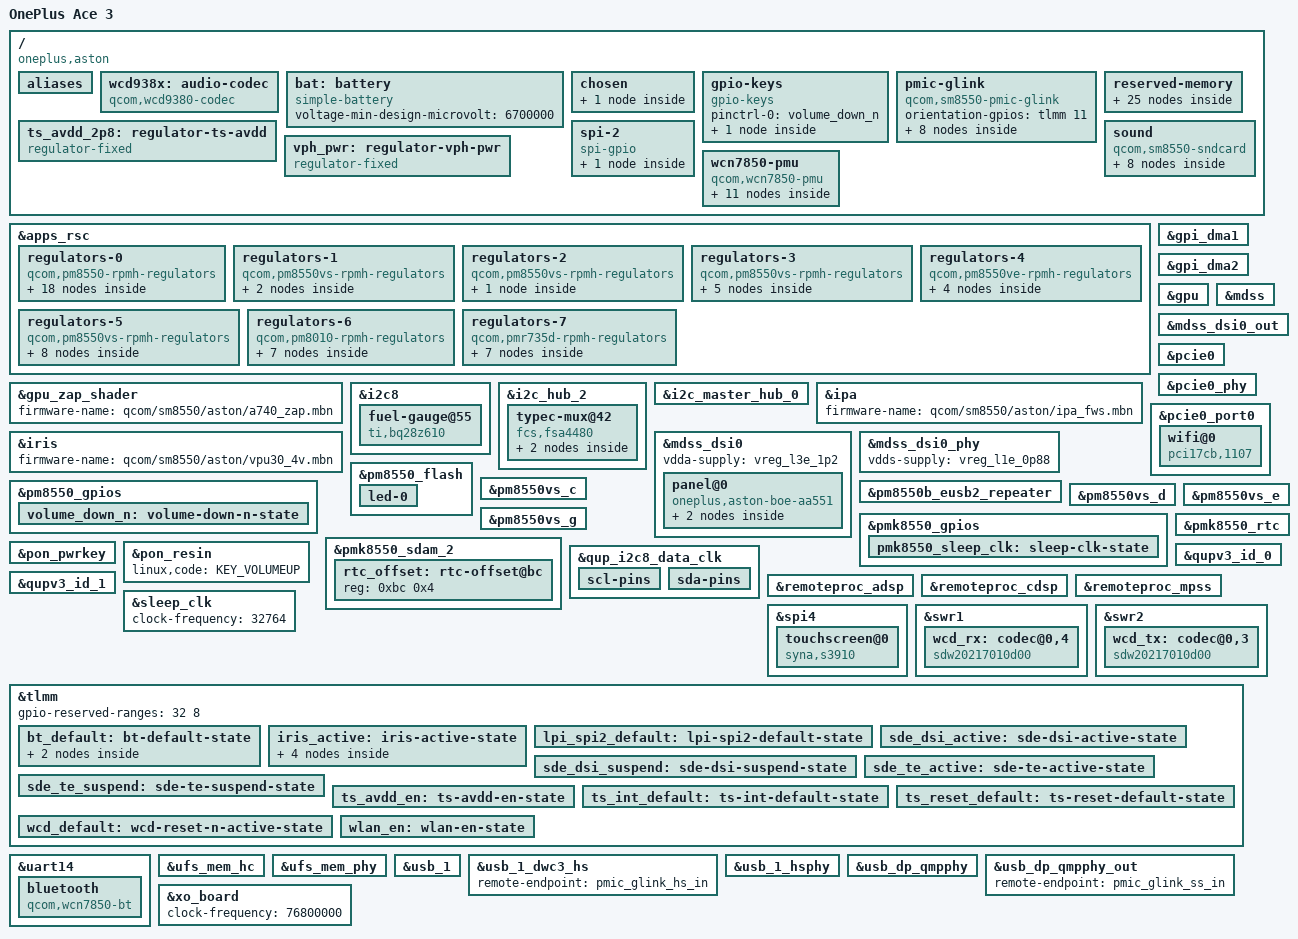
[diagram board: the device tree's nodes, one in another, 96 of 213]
// SPDX-License-Identifier: BSD-3-Clause
/*
 * Copyright (c) 2025, Shandorman <98683030+jiganomegsdfdf@users.noreply.github.com>
 */

/dts-v1/;

#include <dt-bindings/gpio/gpio.h>
#include <dt-bindings/input/linux-event-codes.h>
#include <dt-bindings/leds/common.h>
#include <dt-bindings/regulator/qcom,rpmh-regulator.h>
#include "sm8550.dtsi"
#include "pm8010.dtsi"
#include "pm8550.dtsi"
#include "pm8550b.dtsi"
#define PMK8550VE_SID 5
#include "pm8550ve.dtsi"
#include "pm8550vs.dtsi"
#include "pmk8550.dtsi"
#include "pmr735d_a.dtsi"

/* The second PM8010 (SID 0xd) is not fitted. */
/delete-node/ &pm8010_n;
/delete-node/ &{/thermal-zones/pm8010-n-thermal};
/delete-node/ &reserved_memory;

/ {
	model = "OnePlus Ace 3";
	compatible = "oneplus,aston", "qcom,sm8550";
	chassis-type = "handset";

	aliases {
		serial0 = &uart7;
		serial1 = &uart14;
	};

	wcd938x: audio-codec {
		compatible = "qcom,wcd9380-codec";

		pinctrl-0 = <&wcd_default>;
		pinctrl-names = "default";

		qcom,micbias1-microvolt = <2750000>;
		qcom,micbias2-microvolt = <2750000>;
		qcom,micbias3-microvolt = <2750000>;
		qcom,micbias4-microvolt = <2750000>;
		qcom,mbhc-buttons-vthreshold-microvolt = <75000 150000 237000 500000 500000 500000 500000 500000>;
		qcom,mbhc-headset-vthreshold-microvolt = <1700000>;
		qcom,mbhc-headphone-vthreshold-microvolt = <50000>;
		qcom,rx-device = <&wcd_rx>;
		qcom,tx-device = <&wcd_tx>;

		reset-gpios = <&tlmm 108 GPIO_ACTIVE_LOW>;

		vdd-buck-supply = <&vreg_l15b_1p8>;
		vdd-rxtx-supply = <&vreg_l15b_1p8>;
		vdd-io-supply = <&vreg_l15b_1p8>;
		vdd-mic-bias-supply = <&vreg_bob1>;

		#sound-dai-cells = <1>;
	};

	bat: battery {
		compatible = "simple-battery";

		voltage-min-design-microvolt = <6700000>;
	};

	chosen {
		bootargs = "rdinit=/init panic=0 loglevel=7 log_buf_len=2M bootconfig";

		fdt-handoff {
			stock-compatible = "qcom,kalama";
			stock-bootargs = "oplusboot.prjname=23801",
					 "oplusboot.prjname=23861";
			keep-initrd;
		};
	};

	gpio-keys {
		compatible = "gpio-keys";

		pinctrl-0 = <&volume_down_n>;
		pinctrl-names = "default";

		key-volume-down {
			label = "Volume Down";
			linux,code = <KEY_VOLUMEDOWN>;
			gpios = <&pm8550_gpios 6 GPIO_ACTIVE_LOW>;
			debounce-interval = <15>;
			linux,can-disable;
			wakeup-source;
		};
	};

	pmic-glink {
		compatible = "qcom,sm8550-pmic-glink", "qcom,pmic-glink";
		#address-cells = <1>;
		#size-cells = <0>;
		orientation-gpios = <&tlmm 11 GPIO_ACTIVE_HIGH>;

		connector@0 {
			compatible = "usb-c-connector";
			reg = <0>;
			power-role = "dual";
			data-role = "dual";

			ports {
				#address-cells = <1>;
				#size-cells = <0>;

				port@0 {
					reg = <0>;

					pmic_glink_hs_in: endpoint {
						remote-endpoint = <&usb_1_dwc3_hs>;
					};
				};

				port@1 {
					reg = <1>;

					pmic_glink_ss_in: endpoint {
						remote-endpoint = <&usb_dp_qmpphy_out>;
					};
				};

				port@2 {
					reg = <2>;

					pmic_glink_sbu: endpoint {
						remote-endpoint = <&fsa4480_sbu_mux>;
					};
				};
			};
		};
	};

	/* GPIO 10 switches the touchscreen analog supply; 2.8 V is inferred. */
	ts_avdd_2p8: regulator-ts-avdd {
		compatible = "regulator-fixed";
		regulator-name = "ts_avdd_2p8";
		regulator-min-microvolt = <2800000>;
		regulator-max-microvolt = <2800000>;

		gpio = <&tlmm 10 GPIO_ACTIVE_HIGH>;
		enable-active-high;

		pinctrl-0 = <&ts_avdd_en>;
		pinctrl-names = "default";
	};

	vph_pwr: regulator-vph-pwr {
		compatible = "regulator-fixed";
		regulator-name = "vph_pwr";
		regulator-min-microvolt = <3700000>;
		regulator-max-microvolt = <3700000>;

		regulator-always-on;
		regulator-boot-on;
	};

	reserved-memory {
		#address-cells = <2>;
		#size-cells = <2>;
		ranges;

		hyp_mem: hyp-region@80000000 {
			reg = <0 0x80000000 0 0xa00000>;
			no-map;
		};

		cpusys_vm_mem: cpusys-vm-region@80a00000 {
			reg = <0 0x80a00000 0 0x400000>;
			no-map;
		};

		/* Merged xbl_dt_log, xbl_ramdump and aop_image regions */
		xbl_dt_log_merged_mem: xbl-dt-log-merged-region@81a00000 {
			reg = <0 0x81a00000 0 0x260000>;
			no-map;
		};

		aop_cmd_db_mem: aop-cmd-db-region@81c60000 {
			compatible = "qcom,cmd-db";
			reg = <0 0x81c60000 0 0x20000>;
			no-map;
		};

		/* Merged aop_config, tme_crash_dump, tme_log and uefi_log regions */
		aop_config_merged_mem: aop-config-merged-region@81c80000 {
			reg = <0 0x81c80000 0 0x74000>;
			no-map;
		};

		chipinfo_mem: chipinfo-region@81cf4000 {
			reg = <0 0x81cf4000 0 0x1000>;
			no-map;
		};

		/* Secdata region can be reused by apps */
		smem: smem@81d00000 {
			compatible = "qcom,smem";
			reg = <0 0x81d00000 0 0x200000>;
			hwlocks = <&tcsr_mutex 3>;
			no-map;
		};

		adsp_mhi_mem: adsp-mhi-region@81f00000 {
			reg = <0 0x81f00000 0 0x20000>;
			no-map;
		};

		tz_stat_mem: tz-stat-region@82700000 {
			reg = <0 0x82700000 0 0x100000>;
			no-map;
		};

		mpss_mem: mpss-region@8a800000 {
			reg = <0 0x8a800000 0 0x10800000>;
			no-map;
		};

		q6_mpss_dtb_mem: q6-mpss-dtb-region@9b000000 {
			reg = <0 0x9b000000 0 0x80000>;
			no-map;
		};

		ipa_fw_mem: ipa-fw-region@9b080000 {
			reg = <0 0x9b080000 0 0x10000>;
			no-map;
		};

		ipa_gsi_mem: ipa-gsi-region@9b090000 {
			reg = <0 0x9b090000 0 0xa000>;
			no-map;
		};

		gpu_micro_code_mem: gpu-micro-code-region@9b09a000 {
			reg = <0 0x9b09a000 0 0x2000>;
			no-map;
		};

		video_mem: video-region@9bb00000 {
			reg = <0 0x9bb00000 0 0x700000>;
			no-map;
		};

		cdsp_mem: cdsp-region@9c900000 {
			reg = <0 0x9c900000 0 0x2000000>;
			no-map;
		};

		q6_cdsp_dtb_mem: q6-cdsp-dtb-region@9e900000 {
			reg = <0 0x9e900000 0 0x80000>;
			no-map;
		};

		q6_adsp_dtb_mem: q6-adsp-dtb-region@9e980000 {
			reg = <0 0x9e980000 0 0x80000>;
			no-map;
		};

		adspslpi_mem: adspslpi-region@9ea00000 {
			reg = <0 0x9ea00000 0 0x4880000>;
			no-map;
		};

		mpss_dsm_mem: mpss-dsm-region@d4d00000 {
			reg = <0 0xd4d00000 0 0x3300000>;
			no-map;
		};

		xbl_sc_mem: xbl-sc-region@d8100000 {
			reg = <0 0xd8100000 0 0x40000>;
			no-map;
		};

		cpucp_fw_mem: cpucp-fw-region@d8140000 {
			reg = <0 0xd8140000 0 0x1c0000>;
			no-map;
		};

		qtee_mem: qtee-region@d8300000 {
			reg = <0 0xd8300000 0 0x500000>;
			no-map;
		};

		hwfence_shbuf: hwfence-shbuf-region@e6440000 {
			reg = <0 0xe6440000 0 0x2dd000>;
			no-map;
		};

		rmtfs_mem: rmtfs-region@e8100000 {
			compatible = "qcom,rmtfs-mem";
			reg = <0 0xe8100000 0 0x280000>;
			no-map;

			qcom,client-id = <1>;
			qcom,vmid = <QCOM_SCM_VMID_MSS_MSA>;
		};
	};

	sound {
		compatible = "qcom,sm8550-sndcard", "qcom,sm8450-sndcard";
		model = "astonsnd";
		audio-routing = "IN1_HPHL", "HPHL_OUT",
				"IN2_HPHR", "HPHR_OUT",
				"AMIC1", "MIC BIAS1",
				"AMIC2", "MIC BIAS2",
				"AMIC3", "MIC BIAS3",
				"AMIC4", "MIC BIAS4",
				"AMIC5", "MIC BIAS3",
				"TX SWR_INPUT0", "ADC1_OUTPUT",
				"TX SWR_INPUT1", "ADC2_OUTPUT",
				"TX SWR_INPUT0", "ADC3_OUTPUT",
				"TX SWR_INPUT1", "ADC4_OUTPUT";

		wcd-playback-dai-link {
			link-name = "WCD Playback";

			cpu {
				sound-dai = <&q6apmbedai RX_CODEC_DMA_RX_0>;
			};

			codec {
				sound-dai = <&wcd938x 0>, <&swr1 0>, <&lpass_rxmacro 0>;
			};

			platform {
				sound-dai = <&q6apm>;
			};
		};

		wcd-capture-dai-link {
			link-name = "WCD Capture";

			cpu {
				sound-dai = <&q6apmbedai TX_CODEC_DMA_TX_3>;
			};

			codec {
				sound-dai = <&wcd938x 1>, <&swr2 0>, <&lpass_txmacro 0>;
			};

			platform {
				sound-dai = <&q6apm>;
			};
		};
	};

	/* Bit-banged bus on the LPI pins */
	spi-2 {
		compatible = "spi-gpio";
		#address-cells = <1>;
		#size-cells = <0>;

		miso-gpios = <&tlmm 192 GPIO_ACTIVE_HIGH>;
		mosi-gpios = <&tlmm 193 GPIO_ACTIVE_HIGH>;
		sck-gpios = <&tlmm 194 GPIO_ACTIVE_HIGH>;
		cs-gpios = <&tlmm 195 GPIO_ACTIVE_HIGH>;
		num-chipselects = <1>;

		pinctrl-0 = <&lpi_spi2_default>;
		pinctrl-names = "default";

		imu@0 {
			compatible = "bosch,bmi260";
			reg = <0>;
			spi-max-frequency = <9600000>;

			interrupt-parent = <&tlmm>;
			interrupts = <84 IRQ_TYPE_LEVEL_HIGH>;

			vdd-supply = <&vreg_l1b_1p8>;
			vddio-supply = <&vreg_l1b_1p8>;
		};
	};

	wcn7850-pmu {
		compatible = "qcom,wcn7850-pmu";

		pinctrl-0 = <&wlan_en>, <&bt_default>, <&pmk8550_sleep_clk>;
		pinctrl-names = "default";

		wlan-enable-gpios = <&tlmm 80 GPIO_ACTIVE_HIGH>;
		bt-enable-gpios = <&tlmm 81 GPIO_ACTIVE_HIGH>;

		vdd-supply = <&vreg_s5g_0p8>;
		vddio-supply = <&vreg_l15b_1p8>;
		vddaon-supply = <&vreg_s2g_0p8>;
		vdddig-supply = <&vreg_s4e_0p9>;
		vddrfa1p2-supply = <&vreg_s4g_1p3>;
		vddrfa1p8-supply = <&vreg_s6g_1p8>;

		regulators {
			vreg_pmu_rfa_cmn: ldo0 {
				regulator-name = "vreg_pmu_rfa_cmn";
			};

			vreg_pmu_aon_0p59: ldo1 {
				regulator-name = "vreg_pmu_aon_0p59";
			};

			vreg_pmu_wlcx_0p8: ldo2 {
				regulator-name = "vreg_pmu_wlcx_0p8";
			};

			vreg_pmu_wlmx_0p85: ldo3 {
				regulator-name = "vreg_pmu_wlmx_0p85";
			};

			vreg_pmu_btcmx_0p85: ldo4 {
				regulator-name = "vreg_pmu_btcmx_0p85";
			};

			vreg_pmu_rfa_0p8: ldo5 {
				regulator-name = "vreg_pmu_rfa_0p8";
			};

			vreg_pmu_rfa_1p2: ldo6 {
				regulator-name = "vreg_pmu_rfa_1p2";
			};

			vreg_pmu_rfa_1p8: ldo7 {
				regulator-name = "vreg_pmu_rfa_1p8";
			};

			vreg_pmu_pcie_0p9: ldo8 {
				regulator-name = "vreg_pmu_pcie_0p9";
			};

			vreg_pmu_pcie_1p8: ldo9 {
				regulator-name = "vreg_pmu_pcie_1p8";
			};
		};
	};
};

&apps_rsc {
	regulators-0 {
		compatible = "qcom,pm8550-rpmh-regulators";
		qcom,pmic-id = "b";

		vdd-bob1-supply = <&vph_pwr>;
		vdd-bob2-supply = <&vph_pwr>;
		vdd-l1-l4-l10-supply = <&vreg_s6g_1p8>;
		vdd-l2-l13-l14-supply = <&vreg_bob1>;
		vdd-l3-supply = <&vreg_s4g_1p3>;
		vdd-l5-l16-supply = <&vreg_bob1>;
		vdd-l6-l7-supply = <&vreg_bob1>;
		vdd-l8-l9-supply = <&vreg_bob1>;
		vdd-l11-supply = <&vreg_s4g_1p3>;
		vdd-l12-supply = <&vreg_s6g_1p8>;
		vdd-l15-supply = <&vreg_s6g_1p8>;
		vdd-l17-supply = <&vreg_bob2>;

		vreg_bob1: bob1 {
			regulator-name = "vreg_bob1";
			regulator-min-microvolt = <3008000>;
			regulator-max-microvolt = <3960000>;
			regulator-initial-mode = <RPMH_REGULATOR_MODE_HPM>;
		};

		vreg_bob2: bob2 {
			regulator-name = "vreg_bob2";
			regulator-min-microvolt = <2720000>;
			regulator-max-microvolt = <3008000>;
			regulator-initial-mode = <RPMH_REGULATOR_MODE_HPM>;
		};

		vreg_l1b_1p8: ldo1 {
			regulator-name = "vreg_l1b_1p8";
			regulator-min-microvolt = <1800000>;
			regulator-max-microvolt = <1800000>;
			regulator-initial-mode = <RPMH_REGULATOR_MODE_HPM>;
		};

		vreg_l2b_3p0: ldo2 {
			regulator-name = "vreg_l2b_3p0";
			regulator-min-microvolt = <3008000>;
			regulator-max-microvolt = <3008000>;
			regulator-initial-mode = <RPMH_REGULATOR_MODE_HPM>;
		};

		vreg_l4b_1p8: ldo4 {
			regulator-name = "vreg_l4b_1p8";
			regulator-min-microvolt = <1800000>;
			regulator-max-microvolt = <1800000>;
			regulator-initial-mode = <RPMH_REGULATOR_MODE_HPM>;
		};

		vreg_l5b_3p1: ldo5 {
			regulator-name = "vreg_l5b_3p1";
			regulator-min-microvolt = <3104000>;
			regulator-max-microvolt = <3104000>;
			regulator-initial-mode = <RPMH_REGULATOR_MODE_HPM>;
		};

		vreg_l6b_1p8: ldo6 {
			regulator-name = "vreg_l6b_1p8";
			regulator-min-microvolt = <1800000>;
			regulator-max-microvolt = <3008000>;
			regulator-initial-mode = <RPMH_REGULATOR_MODE_HPM>;
		};

		vreg_l7b_1p8: ldo7 {
			regulator-name = "vreg_l7b_1p8";
			regulator-min-microvolt = <1800000>;
			regulator-max-microvolt = <3008000>;
			regulator-initial-mode = <RPMH_REGULATOR_MODE_HPM>;
		};

		vreg_l8b_1p8: ldo8 {
			regulator-name = "vreg_l8b_1p8";
			regulator-min-microvolt = <1800000>;
			regulator-max-microvolt = <1800000>;
			regulator-initial-mode = <RPMH_REGULATOR_MODE_HPM>;
			regulator-always-on;
			regulator-boot-on;
		};

		vreg_l9b_3p3: ldo9 {
			regulator-name = "vreg_l9b_3p3";
			regulator-min-microvolt = <2960000>;
			regulator-max-microvolt = <3008000>;
			regulator-initial-mode = <RPMH_REGULATOR_MODE_HPM>;
		};

		vreg_l10b_1p8: ldo10 {
			regulator-name = "vreg_l10b_1p8";
			regulator-min-microvolt = <1800000>;
			regulator-max-microvolt = <1800000>;
			regulator-initial-mode = <RPMH_REGULATOR_MODE_HPM>;
			regulator-always-on;
		};

		vreg_l11b_1p2: ldo11 {
			regulator-name = "vreg_l11b_1p2";
			regulator-min-microvolt = <1200000>;
			regulator-max-microvolt = <1504000>;
			regulator-initial-mode = <RPMH_REGULATOR_MODE_HPM>;
		};

		vreg_l12b_1p8: ldo12 {
			regulator-name = "vreg_l12b_1p8";
			regulator-min-microvolt = <1800000>;
			regulator-max-microvolt = <1800000>;
			regulator-initial-mode = <RPMH_REGULATOR_MODE_HPM>;
		};

		vreg_l13b_3p3: ldo13 {
			regulator-name = "vreg_l13b_3p3";
			regulator-min-microvolt = <3000000>;
			regulator-max-microvolt = <3200000>;
			regulator-initial-mode = <RPMH_REGULATOR_MODE_HPM>;
		};

		vreg_l14b_3p2: ldo14 {
			regulator-name = "vreg_l14b_3p2";
			regulator-min-microvolt = <2800000>;
			regulator-max-microvolt = <3200000>;
			regulator-initial-mode = <RPMH_REGULATOR_MODE_HPM>;
		};

		vreg_l15b_1p8: ldo15 {
			regulator-name = "vreg_l15b_1p8";
			regulator-min-microvolt = <1800000>;
			regulator-max-microvolt = <1800000>;
			regulator-initial-mode = <RPMH_REGULATOR_MODE_HPM>;
			regulator-always-on;
		};

		vreg_l16b_2p8: ldo16 {
			regulator-name = "vreg_l16b_2p8";
			regulator-min-microvolt = <2800000>;
			regulator-max-microvolt = <2800000>;
			regulator-initial-mode = <RPMH_REGULATOR_MODE_HPM>;
		};

		vreg_l17b_2p5: ldo17 {
			regulator-name = "vreg_l17b_2p5";
			regulator-min-microvolt = <2504000>;
			regulator-max-microvolt = <2504000>;
			regulator-initial-mode = <RPMH_REGULATOR_MODE_HPM>;
		};
	};

	regulators-1 {
		compatible = "qcom,pm8550vs-rpmh-regulators";
		qcom,pmic-id = "c";

		vdd-l3-supply = <&vreg_s4e_0p9>;

		vreg_l1c_0p91: ldo1 {
			regulator-name = "vreg_l1c_0p9";
			regulator-min-microvolt = <1200000>;
			regulator-max-microvolt = <1200000>;
			regulator-initial-mode = <RPMH_REGULATOR_MODE_HPM>;
		};

		vreg_l3c_0p91: ldo3 {
			regulator-name = "vreg_l3c_0p9";
			regulator-min-microvolt = <880000>;
			regulator-max-microvolt = <912000>;
			regulator-initial-mode = <RPMH_REGULATOR_MODE_HPM>;
		};
	};

	regulators-2 {
		compatible = "qcom,pm8550vs-rpmh-regulators";
		qcom,pmic-id = "d";

		vdd-l1-supply = <&vreg_s4e_0p9>;

		vreg_l1d_0p88: ldo1 {
			regulator-name = "vreg_l1d_0p88";
			regulator-min-microvolt = <880000>;
			regulator-max-microvolt = <920000>;
			regulator-initial-mode = <RPMH_REGULATOR_MODE_HPM>;
		};
	};

	regulators-3 {
		compatible = "qcom,pm8550vs-rpmh-regulators";
		qcom,pmic-id = "e";

		vdd-l1-supply = <&vreg_s4e_0p9>;
		vdd-l2-supply = <&vreg_s4e_0p9>;
		vdd-l3-supply = <&vreg_s4g_1p3>;
		vdd-s4-supply = <&vph_pwr>;
		vdd-s5-supply = <&vph_pwr>;

		vreg_s4e_0p9: smps4 {
			regulator-name = "vreg_s4e_0p9";
			regulator-min-microvolt = <904000>;
			regulator-max-microvolt = <984000>;
			regulator-initial-mode = <RPMH_REGULATOR_MODE_HPM>;
		};

		vreg_s5e_1p1: smps5 {
			regulator-name = "vreg_s5e_1p1";
			regulator-min-microvolt = <1008000>;
			regulator-max-microvolt = <1120000>;
			regulator-initial-mode = <RPMH_REGULATOR_MODE_HPM>;
		};

		vreg_l1e_0p88: ldo1 {
			regulator-name = "vreg_l1e_0p88";
			regulator-min-microvolt = <880000>;
			regulator-max-microvolt = <912000>;
			regulator-initial-mode = <RPMH_REGULATOR_MODE_HPM>;
		};

		vreg_l2e_0p9: ldo2 {
			regulator-name = "vreg_l2e_0p9";
			regulator-min-microvolt = <864000>;
			regulator-max-microvolt = <970000>;
			regulator-initial-mode = <RPMH_REGULATOR_MODE_HPM>;
		};

		vreg_l3e_1p2: ldo3 {
			regulator-name = "vreg_l3e_1p2";
			regulator-min-microvolt = <1200000>;
			regulator-max-microvolt = <1200000>;
			regulator-initial-mode = <RPMH_REGULATOR_MODE_HPM>;
		};
	};

	regulators-4 {
		compatible = "qcom,pm8550ve-rpmh-regulators";
		qcom,pmic-id = "f";

		vdd-l1-supply = <&vreg_s4e_0p9>;
		vdd-l2-supply = <&vreg_s4e_0p9>;
		vdd-l3-supply = <&vreg_s4e_0p9>;
		vdd-s4-supply = <&vph_pwr>;

		vreg_s4f_0p5: smps4 {
			regulator-name = "vreg_s4f_0p5";
			regulator-min-microvolt = <300000>;
			regulator-max-microvolt = <700000>;
			regulator-initial-mode = <RPMH_REGULATOR_MODE_HPM>;
		};

		vreg_l1f_0p9: ldo1 {
			regulator-name = "vreg_l1f_0p9";
			regulator-min-microvolt = <880000>;
			regulator-max-microvolt = <912000>;
			regulator-initial-mode = <RPMH_REGULATOR_MODE_HPM>;
		};

		vreg_l2f_0p88: ldo2 {
			regulator-name = "vreg_l2f_0p88";
			regulator-min-microvolt = <880000>;
			regulator-max-microvolt = <912000>;
			regulator-initial-mode = <RPMH_REGULATOR_MODE_HPM>;
		};

		vreg_l3f_0p91: ldo3 {
			regulator-name = "vreg_l3f_0p91";
			regulator-min-microvolt = <880000>;
			regulator-max-microvolt = <912000>;
			regulator-initial-mode = <RPMH_REGULATOR_MODE_HPM>;
		};
	};

	regulators-5 {
		compatible = "qcom,pm8550vs-rpmh-regulators";
		qcom,pmic-id = "g";

		vdd-l1-supply = <&vreg_s4g_1p3>;
		vdd-l2-supply = <&vreg_s4g_1p3>;
		vdd-l3-supply = <&vreg_s4g_1p3>;
		vdd-s1-supply = <&vph_pwr>;
		vdd-s2-supply = <&vph_pwr>;
		vdd-s3-supply = <&vph_pwr>;
		vdd-s4-supply = <&vph_pwr>;
		vdd-s5-supply = <&vph_pwr>;
		vdd-s6-supply = <&vph_pwr>;

		vreg_s1g_1p2: smps1 {
			regulator-name = "vreg_s1g_1p2";
			regulator-min-microvolt = <1200000>;
			regulator-max-microvolt = <1300000>;
			regulator-initial-mode = <RPMH_REGULATOR_MODE_HPM>;
		};

		vreg_s2g_0p8: smps2 {
			regulator-name = "vreg_s2g_0p8";
			regulator-min-microvolt = <500000>;
			regulator-max-microvolt = <1036000>;
			regulator-initial-mode = <RPMH_REGULATOR_MODE_HPM>;
		};

		vreg_s4g_1p3: smps4 {
			regulator-name = "vreg_s4g_1p3";
			regulator-min-microvolt = <1200000>;
			regulator-max-microvolt = <1352000>;
			regulator-initial-mode = <RPMH_REGULATOR_MODE_HPM>;
		};

		vreg_s5g_0p8: smps5 {
			regulator-name = "vreg_s5g_0p8";
			regulator-min-microvolt = <500000>;
			regulator-max-microvolt = <1004000>;
			regulator-initial-mode = <RPMH_REGULATOR_MODE_HPM>;
		};

		vreg_s6g_1p8: smps6 {
			regulator-name = "vreg_s6g_1p8";
			regulator-min-microvolt = <1800000>;
			regulator-max-microvolt = <2000000>;
			regulator-initial-mode = <RPMH_REGULATOR_MODE_HPM>;
		};

		vreg_l1g_1p2: ldo1 {
			regulator-name = "vreg_l1g_1p2";
			regulator-min-microvolt = <1144000>;
			regulator-max-microvolt = <1256000>;
			regulator-initial-mode = <RPMH_REGULATOR_MODE_HPM>;
		};

		vreg_l2g_1p2: ldo2 {
			regulator-name = "vreg_l2g_1p2";
			regulator-min-microvolt = <1056000>;
			regulator-max-microvolt = <1056000>;
			regulator-initial-mode = <RPMH_REGULATOR_MODE_HPM>;
		};

		vreg_l3g_1p2: ldo3 {
			regulator-name = "vreg_l3g_1p2";
			regulator-min-microvolt = <1200000>;
			regulator-max-microvolt = <1200000>;
			regulator-initial-mode = <RPMH_REGULATOR_MODE_HPM>;
		};
	};

	regulators-6 {
		compatible = "qcom,pm8010-rpmh-regulators";
		qcom,pmic-id = "m";

		vdd-l1-l2-supply = <&vreg_s4g_1p3>;
		vdd-l3-l4-supply = <&vreg_bob2>;
		vdd-l5-supply = <&vreg_s6g_1p8>;
		vdd-l6-supply = <&vreg_s6g_1p8>;
		vdd-l7-supply = <&vreg_bob1>;

		vreg_l1m_1p2: ldo1 {
			regulator-name = "vreg_l1m_1p2";
			regulator-min-microvolt = <1200000>;
			regulator-max-microvolt = <1200000>;
			regulator-initial-mode = <RPMH_REGULATOR_MODE_HPM>;
		};

		vreg_l2m_1p08: ldo2 {
			regulator-name = "vreg_l2m_1p08";
			regulator-min-microvolt = <1200000>;
			regulator-max-microvolt = <1200000>;
			regulator-initial-mode = <RPMH_REGULATOR_MODE_HPM>;
		};

		vreg_l3m_2p8: ldo3 {
			regulator-name = "vreg_l3m_2p8";
			regulator-min-microvolt = <2800000>;
			regulator-max-microvolt = <2800000>;
			regulator-initial-mode = <RPMH_REGULATOR_MODE_HPM>;
		};

		vreg_l4m_2p8: ldo4 {
			regulator-name = "vreg_l4m_2p8";
			regulator-min-microvolt = <2800000>;
			regulator-max-microvolt = <2800000>;
			regulator-initial-mode = <RPMH_REGULATOR_MODE_HPM>;
		};

		vreg_l5m_1p8: ldo5 {
			regulator-name = "vreg_l5m_1p8";
			regulator-min-microvolt = <1800000>;
			regulator-max-microvolt = <1800000>;
			regulator-initial-mode = <RPMH_REGULATOR_MODE_HPM>;
		};

		vreg_l6m_2p8: ldo6 {
			regulator-name = "vreg_l6m_2p8";
			regulator-min-microvolt = <2848000>;
			regulator-max-microvolt = <2848000>;
			regulator-initial-mode = <RPMH_REGULATOR_MODE_HPM>;
		};

		vreg_l7m_2p85: ldo7 {
			regulator-name = "vreg_l7m_2p85";
			regulator-min-microvolt = <2800000>;
			regulator-max-microvolt = <2800000>;
			regulator-initial-mode = <RPMH_REGULATOR_MODE_HPM>;
		};
	};

	regulators-7 {
		compatible = "qcom,pmr735d-rpmh-regulators";
		qcom,pmic-id = "k";

		vdd-l1-l2-l5-supply = <&vreg_s2g_0p8>;
		vdd-l3-l4-supply = <&vreg_s1g_1p2>;
		vdd-l6-supply = <&vreg_s6g_1p8>;
		vdd-l7-supply = <&vreg_s1g_1p2>;

		vreg_l1k_0p4: ldo1 {
			regulator-name = "vreg_l1k_0p4";
			regulator-min-microvolt = <400000>;
			regulator-max-microvolt = <900000>;
			regulator-initial-mode = <RPMH_REGULATOR_MODE_HPM>;
		};

		vreg_l2k_0p5: ldo2 {
			regulator-name = "vreg_l2k_0p5";
			regulator-min-microvolt = <500000>;
			regulator-max-microvolt = <900000>;
			regulator-initial-mode = <RPMH_REGULATOR_MODE_HPM>;
		};

		vreg_l3k_0p88: ldo3 {
			regulator-name = "vreg_l3k_0p88";
			regulator-min-microvolt = <880000>;
			regulator-max-microvolt = <912000>;
			regulator-initial-mode = <RPMH_REGULATOR_MODE_HPM>;
		};

		vreg_l4k_1p2: ldo4 {
			regulator-name = "vreg_l4k_1p2";
			regulator-min-microvolt = <1200000>;
			regulator-max-microvolt = <1200000>;
			regulator-initial-mode = <RPMH_REGULATOR_MODE_HPM>;
		};

		vreg_l5k_0p8: ldo5 {
			regulator-name = "vreg_l5k_0p8";
			regulator-min-microvolt = <800000>;
			regulator-max-microvolt = <800000>;
			regulator-initial-mode = <RPMH_REGULATOR_MODE_HPM>;
		};

		vreg_l6k_1p77: ldo6 {
			regulator-name = "vreg_l6k_1p77";
			regulator-min-microvolt = <1776000>;
			regulator-max-microvolt = <1900000>;
			regulator-initial-mode = <RPMH_REGULATOR_MODE_HPM>;
		};

		vreg_l7k_1p2: ldo7 {
			regulator-name = "vreg_l7k_1p2";
			regulator-min-microvolt = <1200000>;
			regulator-max-microvolt = <1200000>;
			regulator-initial-mode = <RPMH_REGULATOR_MODE_HPM>;
		};
	};
};

&gpi_dma1 {
	status = "okay";
};

&gpi_dma2 {
	status = "okay";
};

&gpu {
	status = "okay";
};

&gpu_zap_shader {
	firmware-name = "qcom/sm8550/aston/a740_zap.mbn";
};

&i2c8 {
	status = "okay";

	fuel-gauge@55 {
		compatible = "ti,bq28z610";
		reg = <0x55>;
		monitored-battery = <&bat>;
	};
};

&i2c_hub_2 {
	status = "okay";

	typec-mux@42 {
		compatible = "fcs,fsa4480";
		reg = <0x42>;

		vcc-supply = <&vreg_bob1>;

		mode-switch;
		orientation-switch;

		port {
			fsa4480_sbu_mux: endpoint {
				remote-endpoint = <&pmic_glink_sbu>;
			};
		};
	};
};

&i2c_master_hub_0 {
	status = "okay";
};

&ipa {
	firmware-name = "qcom/sm8550/aston/ipa_fws.mbn";

	status = "okay";
};

&iris {
	firmware-name = "qcom/sm8550/aston/vpu30_4v.mbn";

	status = "okay";
};

&mdss {
	status = "okay";
};

&mdss_dsi0 {
	vdda-supply = <&vreg_l3e_1p2>;

	status = "okay";

	panel@0 {
		compatible = "oneplus,aston-boe-aa551";
		reg = <0>;

		reset-gpios = <&tlmm 133 GPIO_ACTIVE_LOW>;

		vddio-supply = <&vreg_l12b_1p8>;
		vci-supply = <&vreg_l13b_3p3>;

		iris-vdd0p9-gpios = <&tlmm 105 GPIO_ACTIVE_HIGH>;
		iris-reset-gpios = <&tlmm 109 GPIO_ACTIVE_LOW>;
		iris-wakeup-gpios = <&tlmm 129 GPIO_ACTIVE_HIGH>;
		iris-abyp-ready-gpios = <&tlmm 181 GPIO_ACTIVE_HIGH>;

		pinctrl-0 = <&sde_dsi_active>, <&sde_te_active>, <&iris_active>;
		pinctrl-1 = <&sde_dsi_suspend>, <&sde_te_suspend>;
		pinctrl-names = "default", "sleep";

		port {
			panel_in: endpoint {
				remote-endpoint = <&mdss_dsi0_out>;
			};
		};
	};
};

&mdss_dsi0_out {
	remote-endpoint = <&panel_in>;
	data-lanes = <0 1 2 3>;
};

&mdss_dsi0_phy {
	vdds-supply = <&vreg_l1e_0p88>;

	status = "okay";
};

&pcie0 {
	/* WCN7850 WAKE# is asserted low and idles high. */
	wake-gpios = <&tlmm 96 GPIO_ACTIVE_LOW>;
	perst-gpios = <&tlmm 94 GPIO_ACTIVE_LOW>;

	pinctrl-0 = <&pcie0_default_state>;
	pinctrl-names = "default";

	status = "okay";
};

&pcie0_phy {
	vdda-phy-supply = <&vreg_l1e_0p88>;
	vdda-pll-supply = <&vreg_l3e_1p2>;

	status = "okay";
};

&pcie0_port0 {
	wifi@0 {
		compatible = "pci17cb,1107";
		reg = <0x10000 0x0 0x0 0x0 0x0>;

		vddrfacmn-supply = <&vreg_pmu_rfa_cmn>;
		vddaon-supply = <&vreg_pmu_aon_0p59>;
		vddwlcx-supply = <&vreg_pmu_wlcx_0p8>;
		vddwlmx-supply = <&vreg_pmu_wlmx_0p85>;
		vddrfa0p8-supply = <&vreg_pmu_rfa_0p8>;
		vddrfa1p2-supply = <&vreg_pmu_rfa_1p2>;
		vddrfa1p8-supply = <&vreg_pmu_rfa_1p8>;
		vddpcie0p9-supply = <&vreg_pmu_pcie_0p9>;
		vddpcie1p8-supply = <&vreg_pmu_pcie_1p8>;
	};
};

&pm8550_flash {
	status = "okay";

	led-0 {
		function = LED_FUNCTION_FLASH;
		color = <LED_COLOR_ID_WHITE>;
		led-sources = <1>, <4>;
		led-max-microamp = <500000>;
		flash-max-microamp = <2000000>;
		flash-max-timeout-us = <1280000>;
		function-enumerator = <0>;
	};
};

&pm8550_gpios {
	volume_down_n: volume-down-n-state {
		pins = "gpio6";
		function = "normal";
		power-source = <1>;
		bias-pull-up;
		input-enable;
	};
};

&pm8550b_eusb2_repeater {
	vdd18-supply = <&vreg_l15b_1p8>;
	vdd3-supply = <&vreg_l5b_3p1>;
};

&pm8550vs_c {
	status = "okay";
};

&pm8550vs_d {
	status = "okay";
};

&pm8550vs_e {
	status = "okay";
};

&pm8550vs_g {
	status = "okay";
};

&pmk8550_gpios {
	pmk8550_sleep_clk: sleep-clk-state {
		pins = "gpio3";
		function = "func1";
		input-disable;
		output-enable;
		bias-disable;
		power-source = <0>;
	};
};

&pmk8550_rtc {
	nvmem-cells = <&rtc_offset>;
	nvmem-cell-names = "offset";
};

&pmk8550_sdam_2 {
	rtc_offset: rtc-offset@bc {
		reg = <0xbc 0x4>;
	};
};

&pon_pwrkey {
	status = "okay";
};

&pon_resin {
	linux,code = <KEY_VOLUMEUP>;

	status = "okay";
};

&qup_i2c8_data_clk {
	/* The fuel gauge bus uses the mirror B pins, GPIO 0 and 1. */
	scl-pins {
		pins = "gpio1";
		function = "qup2_se0_l1_mirb";
	};

	sda-pins {
		pins = "gpio0";
		function = "qup2_se0_l0_mirb";
	};
};

&qupv3_id_0 {
	status = "okay";
};

&qupv3_id_1 {
	status = "okay";
};

&remoteproc_adsp {
	firmware-name = "qcom/sm8550/aston/adsp.mbn",
			"qcom/sm8550/aston/adsp_dtb.mbn";

	status = "okay";
};

&remoteproc_cdsp {
	firmware-name = "qcom/sm8550/aston/cdsp.mbn",
			"qcom/sm8550/aston/cdsp_dtb.mbn";

	status = "okay";
};

&remoteproc_mpss {
	firmware-name = "qcom/sm8550/aston/modem.mbn",
			"qcom/sm8550/aston/modem_dtb.mbn";
};

&sleep_clk {
	clock-frequency = <32764>;
};

&spi4 {
	status = "okay";

	touchscreen@0 {
		compatible = "syna,s3910";
		reg = <0>;
		spi-max-frequency = <19000000>;

		interrupts-extended = <&tlmm 25 IRQ_TYPE_LEVEL_LOW>;
		reset-gpios = <&tlmm 24 GPIO_ACTIVE_LOW>;

		vdd-supply = <&vreg_l4b_1p8>;
		avdd-supply = <&ts_avdd_2p8>;

		pinctrl-0 = <&ts_int_default>, <&ts_reset_default>;
		pinctrl-names = "default";
	};
};

&swr1 {
	status = "okay";

	/* WCD9380 RX */
	wcd_rx: codec@0,4 {
		compatible = "sdw20217010d00";
		reg = <0 4>;
		qcom,rx-port-mapping = <1 2 3 4 5>;
	};
};

&swr2 {
	status = "okay";

	/* WCD9380 TX */
	wcd_tx: codec@0,3 {
		compatible = "sdw20217010d00";
		reg = <0 3>;
		qcom,tx-port-mapping = <2 2 3 4>;
	};
};

&tlmm {
	gpio-reserved-ranges = <32 8>;

	bt_default: bt-default-state {
		bt-en-pins {
			pins = "gpio81";
			function = "gpio";
			drive-strength = <16>;
			bias-disable;
		};

		sw-ctrl-pins {
			pins = "gpio82";
			function = "gpio";
			bias-pull-down;
		};
	};

	iris_active: iris-active-state {
		vdd0p9-pins {
			pins = "gpio105";
			function = "gpio";
			drive-strength = <8>;
			bias-pull-up;
		};

		reset-pins {
			pins = "gpio109";
			function = "gpio";
			drive-strength = <8>;
			bias-disable;
		};

		wakeup-pins {
			pins = "gpio129";
			function = "gpio";
			drive-strength = <8>;
			bias-disable;
			output-low;
		};

		ready-pins {
			pins = "gpio181";
			function = "gpio";
			drive-strength = <8>;
			bias-disable;
		};
	};

	lpi_spi2_default: lpi-spi2-default-state {
		/* MISO, MOSI, CLK, CS */
		pins = "gpio192", "gpio193", "gpio194", "gpio195";
		function = "gpio";
	};

	sde_dsi_active: sde-dsi-active-state {
		pins = "gpio133";
		function = "gpio";
		drive-strength = <8>;
		bias-disable;
	};

	sde_dsi_suspend: sde-dsi-suspend-state {
		pins = "gpio133";
		function = "gpio";
		drive-strength = <2>;
		bias-pull-down;
	};

	sde_te_active: sde-te-active-state {
		pins = "gpio86";
		function = "mdp_vsync";
		drive-strength = <2>;
		bias-pull-down;
	};

	sde_te_suspend: sde-te-suspend-state {
		pins = "gpio86";
		function = "mdp_vsync";
		drive-strength = <2>;
		bias-pull-down;
	};

	ts_avdd_en: ts-avdd-en-state {
		pins = "gpio10";
		function = "gpio";
		drive-strength = <2>;
		bias-disable;
	};

	ts_int_default: ts-int-default-state {
		pins = "gpio25";
		function = "gpio";
		drive-strength = <8>;
		bias-pull-up;
	};

	ts_reset_default: ts-reset-default-state {
		pins = "gpio24";
		function = "gpio";
		drive-strength = <8>;
		bias-disable;
	};

	wcd_default: wcd-reset-n-active-state {
		pins = "gpio108";
		function = "gpio";
		drive-strength = <16>;
		bias-disable;
		output-low;
	};

	wlan_en: wlan-en-state {
		pins = "gpio80";
		function = "gpio";
		drive-strength = <8>;
		bias-pull-down;
	};
};

&uart14 {
	status = "okay";

	bluetooth {
		compatible = "qcom,wcn7850-bt";

		vddrfacmn-supply = <&vreg_pmu_rfa_cmn>;
		vddaon-supply = <&vreg_pmu_aon_0p59>;
		vddwlcx-supply = <&vreg_pmu_wlcx_0p8>;
		vddwlmx-supply = <&vreg_pmu_wlmx_0p85>;
		vddrfa0p8-supply = <&vreg_pmu_rfa_0p8>;
		vddrfa1p2-supply = <&vreg_pmu_rfa_1p2>;
		vddrfa1p8-supply = <&vreg_pmu_rfa_1p8>;

		max-speed = <3200000>;
	};
};

&ufs_mem_hc {
	reset-gpios = <&tlmm 210 GPIO_ACTIVE_LOW>;

	vcc-supply = <&vreg_l17b_2p5>;
	vcc-max-microamp = <1300000>;
	vccq-supply = <&vreg_l1g_1p2>;
	vccq-max-microamp = <1200000>;
	vdd-hba-supply = <&vreg_l3g_1p2>;

	status = "okay";
};

&ufs_mem_phy {
	vdda-phy-supply = <&vreg_l1d_0p88>;
	vdda-pll-supply = <&vreg_l3e_1p2>;

	status = "okay";
};

&usb_1 {
	status = "okay";
};

&usb_1_dwc3_hs {
	remote-endpoint = <&pmic_glink_hs_in>;
};

&usb_1_hsphy {
	vdd-supply = <&vreg_l1e_0p88>;
	vdda12-supply = <&vreg_l3e_1p2>;

	phys = <&pm8550b_eusb2_repeater>;

	status = "okay";
};

&usb_dp_qmpphy {
	vdda-phy-supply = <&vreg_l3e_1p2>;
	vdda-pll-supply = <&vreg_l3f_0p91>;

	status = "okay";
};

&usb_dp_qmpphy_out {
	remote-endpoint = <&pmic_glink_ss_in>;
};

&xo_board {
	clock-frequency = <76800000>;
};

#include "sm8550-oneplus-aston-thermal.dtsi"
